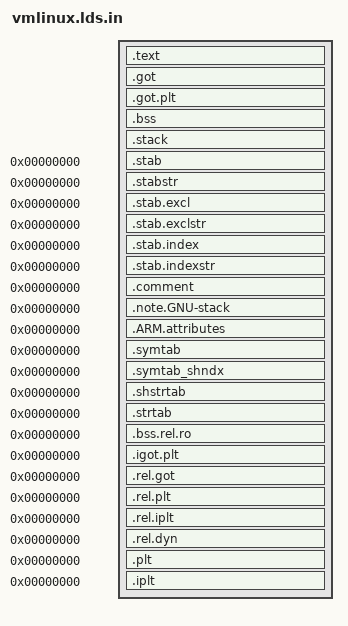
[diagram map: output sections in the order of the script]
/*
 *  linux/arch/arm/boot/compressed/vmlinux.lds.in
 *
 *  Copyright (C) 2000 Russell King
 *
 * This program is free software; you can redistribute it and/or modify
 * it under the terms of the GNU General Public License version 2 as
 * published by the Free Software Foundation.
 */
OUTPUT_ARCH(arm)
ENTRY(_start)
SECTIONS
{
  /DISCARD/ : {
    *(.ARM.exidx*)
    *(.ARM.extab*)
    *(.eh_frame*)
    /*
     * Discard any r/w data - this produces a link error if we have any,
     * which is required for PIC decompression.  Local data generates
     * GOTOFF relocations, which prevents it being relocated independently
     * of the text/got segments.
     */
    *(.data)
  }

  . = TEXT_START;
  _text = .;

  .text : {
    _start = .;
    *(.start)
    *(.text)
    *(.text.*)
    *(.fixup)
    *(.gnu.warning)
    *(.rodata)
    *(.rodata.*)
    *(.glue_7)
    *(.glue_7t)
    *(.v4_bx)
    *(.vfp11_veneer)
    *(.piggydata)
    . = ALIGN(4);
  }

  _etext = .;

  _got_start = .;
  .got			: { *(.got) }
  _got_end = .;
  .got.plt		: { *(.got.plt) }
  _edata = .;

  . = BSS_START;
  __bss_start = .;
  .bss			: { *(.bss) }
  _end = .;

  . = ALIGN(8);		/* the stack must be 64-bit aligned */
  .stack		: { *(.stack) }

  .stab 0		: { *(.stab) }
  .stabstr 0		: { *(.stabstr) }
  .stab.excl 0		: { *(.stab.excl) }
  .stab.exclstr 0	: { *(.stab.exclstr) }
  .stab.index 0		: { *(.stab.index) }
  .stab.indexstr 0	: { *(.stab.indexstr) }
  .comment 0		: { *(.comment) }
  .note.GNU-stack 0	: { *(.note.GNU-stack) }
  .ARM.attributes 0	: { *(.ARM.attributes) }
  .symtab 0		: { *(.symtab) }
  .symtab_shndx 0	: { *(.symtab_shndx) }
  .shstrtab 0		: { *(.shstrtab) }
  .strtab 0		: { *(.strtab) }

  /* The decompressor runs without a dynamic linker. */
  .bss.rel.ro 0		: { *(.bss.rel.ro) }
  .igot.plt 0		: { *(.igot.plt) }
  .rel.got 0		: { *(.rel.got) }
  .rel.plt 0		: { *(.rel.plt) }
  .rel.iplt 0		: { *(.rel.iplt) }
  .rel.dyn 0		: { *(.rel.dyn) }
  .plt 0		: { *(.plt) }
  .iplt 0		: { *(.iplt) }
}

ASSERT(SIZEOF(.bss.rel.ro) == 0, "unexpected relocation BSS")
ASSERT(SIZEOF(.igot.plt) == 0, "unexpected indirect GOT PLT")
ASSERT(SIZEOF(.rel.got) == 0, "unexpected GOT relocations")
ASSERT(SIZEOF(.rel.plt) == 0, "unexpected PLT relocations")
ASSERT(SIZEOF(.rel.iplt) == 0, "unexpected indirect PLT relocations")
ASSERT(SIZEOF(.rel.dyn) == 0, "unexpected dynamic relocations")
ASSERT(SIZEOF(.plt) == 0, "unexpected PLT")
ASSERT(SIZEOF(.iplt) == 0, "unexpected indirect PLT")
